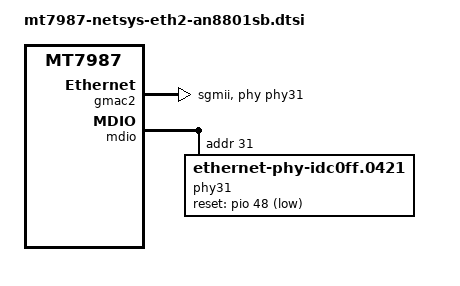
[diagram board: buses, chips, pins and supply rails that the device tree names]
// SPDX-License-Identifier: (GPL-2.0 OR MIT)

&eth {
	gmac2: mac@2 {
		compatible = "mediatek,eth-mac";
		reg = <2>;
		pcs-handle = <&sgmiipcs1>;
		phy-mode = "sgmii";
		phy-handle = <&phy31>;
	};
};

&hnat {
	mtketh-lan2 = "eth2";
	mtketh-max-gmac = <3>;
};

&mdio {
	phy31: phy@31 {
		compatible = "ethernet-phy-idc0ff.0421";
		reg = <31>;
		reset-gpios = <&pio 48 1>;
		reset-assert-us = <10000>;
		reset-deassert-us = <10000>;
		phy-mode = "sgmii";
		eee-broken-100tx;
		eee-broken-1000t;
	};
};

